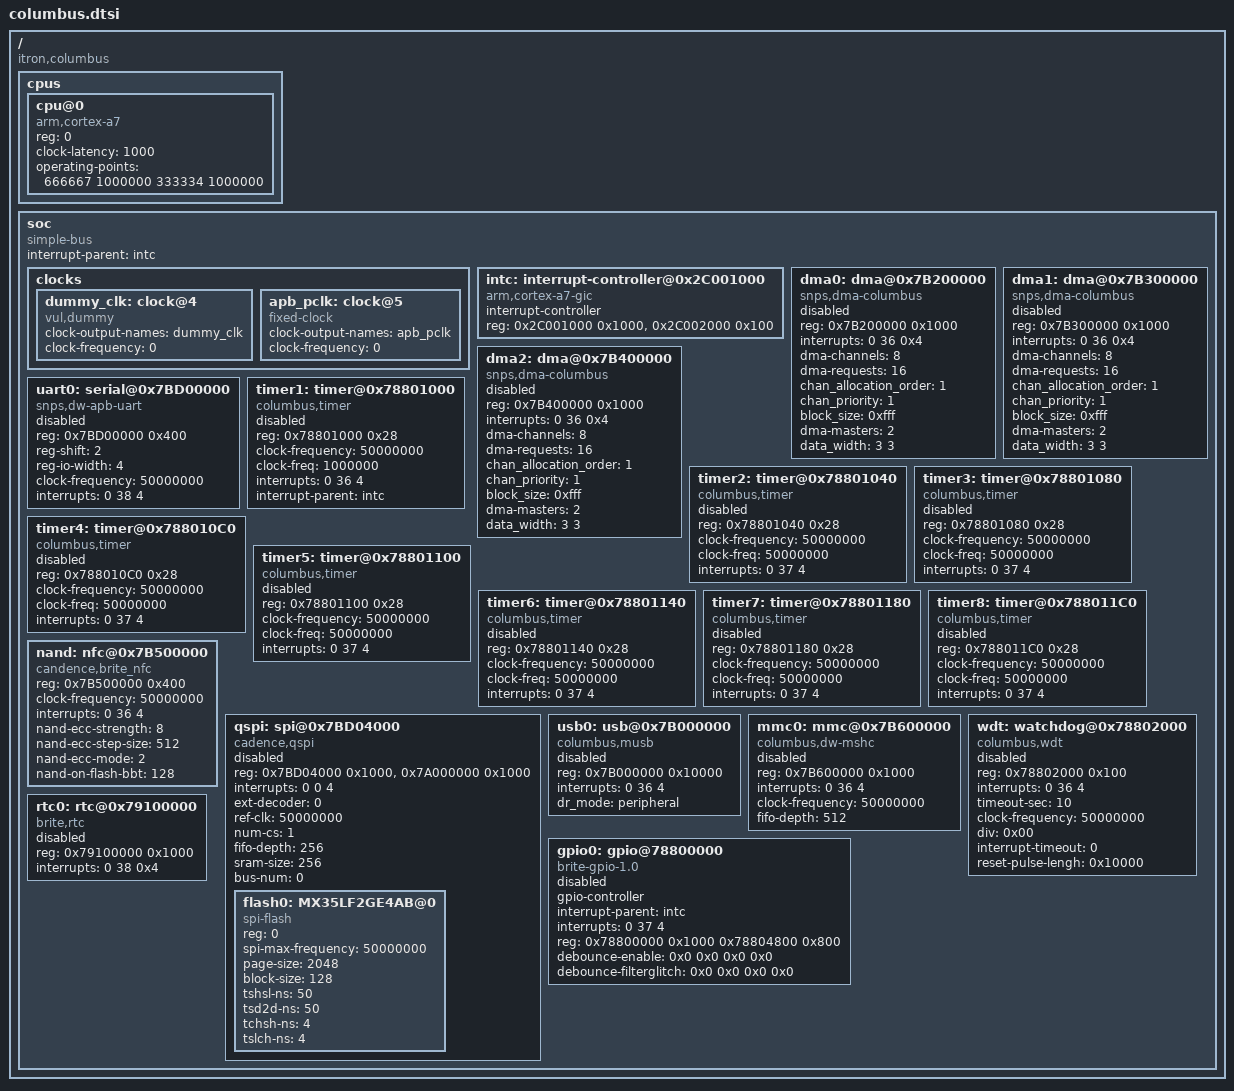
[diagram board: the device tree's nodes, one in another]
#include "skeleton.dtsi"

/ {
	compatible = "itron,columbus";

	cpus {
		#address-cells = <1>;
		#size-cells = <0>;

		cpu@0 {
			compatible = "arm,cortex-a7";
			device_type = "cpu";
			reg = <0>;
			clock-latency = <1000>;
			operating-points = <
				/* kHz    uV */
				666667  1000000
				333334  1000000
			>;
		};
	};

	soc {
		compatible = "simple-bus";
		#address-cells = <1>;
		#size-cells = <1>;
		interrupt-parent = <&intc>;
		ranges;

		clocks {
			dummy_clk: clock@4 {
				compatible = "vul,dummy", "fixed-clock";
				#clock-cells = <0>;
				clock-names = "dummy_clk";
				clock-output-names = "dummy_clk";
				clock-frequency = <0>;
			};
			apb_pclk: clock@5 {
				compatible = "fixed-clock";
				#clock-cells = <0>;
				clock-names = "apb_pclk";
				clock-output-names = "apb_pclk";
				clock-frequency = <0>;
			};
		};

		intc: interrupt-controller@0x2C001000 {
			compatible = "arm,cortex-a7-gic";
			#interrupt-cells = <3>;
			interrupt-controller;
			reg = <0x2C001000 0x1000>,
				<0x2C002000 0x100>;
		};

		dma0: dma@0x7B200000 {
                        compatible = "snps,dma-columbus";
                        reg = <0x7B200000 0x1000>;
                        interrupts = <0 36 0x4>;
                        status = "disabled";

                        dma-channels = <8>;
                        #dma-cells = <3>;
                        dma-requests = <16>;
                        chan_allocation_order = <1>;
                        chan_priority = <1>;
                        block_size = <0xfff>;
                        dma-masters = <2>;
                        data_width = <3 3>;
                };

                dma1: dma@0x7B300000 {
                        compatible = "snps,dma-columbus";
                        reg = <0x7B300000 0x1000>;
                        interrupts = <0 36 0x4>;
                        status = "disabled";

                        dma-channels = <8>;
                        #dma-cells = <3>;
                        dma-requests = <16>;
                        chan_allocation_order = <1>;
                        chan_priority = <1>;
                        block_size = <0xfff>;
                        dma-masters = <2>;
                        data_width = <3 3>;
                };

                dma2: dma@0x7B400000 {
                        compatible = "snps,dma-columbus";
                        reg = <0x7B400000 0x1000>;
                        interrupts = <0 36 0x4>;
                        status = "disabled";

                        dma-channels = <8>;
                        #dma-cells = <3>;
                        dma-requests = <16>;
                        chan_allocation_order = <1>;
                        chan_priority = <1>;
                        block_size = <0xfff>;
                        dma-masters = <2>;
                        data_width = <3 3>;
                };

  		uart0: serial@0x7BD00000 {
			compatible = "snps,dw-apb-uart";
			reg = <0x7BD00000 0x400>;
			reg-shift = <2>;
			reg-io-width = <4>;
			clock-frequency = <50000000>;
			interrupts = <0 38 4>;
			status = "disabled";
		};

		timer1: timer@0x78801000 {
			compatible = "columbus,timer";
			reg = <0x78801000 0x28>;
			clock-frequency = <50000000>;
			clock-freq = <1000000>;
			status = "disabled";
			interrupts = <0 36 4>;
			interrupt-parent = <&intc>;
		};
		timer2: timer@0x78801040 {
			compatible = "columbus,timer";
			reg = <0x78801040 0x28>;
			clock-frequency = <50000000>;
			clock-freq = <50000000>;
			interrupts = <0 37 4>;
			status = "disabled";
		};
		timer3: timer@0x78801080 {
			compatible = "columbus,timer";
			reg = <0x78801080 0x28>;
			clock-frequency = <50000000>;
			clock-freq = <50000000>;
			interrupts = <0 37 4>;
			status = "disabled";
		};
		timer4: timer@0x788010C0 {
			compatible = "columbus,timer";
			reg = <0x788010C0 0x28>;
			clock-frequency = <50000000>;
			clock-freq = <50000000>;
			interrupts = <0 37 4>;
			status = "disabled";
		};
		timer5: timer@0x78801100 {
			compatible = "columbus,timer";
			reg = <0x78801100 0x28>;
			clock-frequency = <50000000>;
			clock-freq = <50000000>;
			interrupts = <0 37 4>;
			status = "disabled";
		};
		timer6: timer@0x78801140 {
			compatible = "columbus,timer";
			reg = <0x78801140 0x28>;
			clock-frequency = <50000000>;
			clock-freq = <50000000>;
			interrupts = <0 37 4>;
			status = "disabled";
		};
		timer7: timer@0x78801180 {
			compatible = "columbus,timer";
			reg = <0x78801180 0x28>;
			clock-frequency = <50000000>;
			clock-freq = <50000000>;
			interrupts = <0 37 4>;
			status = "disabled";
		};
		timer8: timer@0x788011C0 {
			compatible = "columbus,timer";
			reg = <0x788011C0 0x28>;
			clock-frequency = <50000000>;
			clock-freq = <50000000>;
			interrupts = <0 37 4>;
			status = "disabled";
		};

		nand: nfc@0x7B500000 {
			compatible = "candence,brite_nfc";
			reg = <0x7B500000 0x400>;
			clock-frequency = <50000000>;
			interrupts = <0 36 4>;
			nand-ecc-strength = <8>;
			nand-ecc-step-size = <512>;
			nand-ecc-mode  = <2>;
			nand-on-flash-bbt = <128>;
		};
		qspi: spi@0x7BD04000 {
                        compatible = "cadence,qspi";
                        #address-cells = <1>;
                        #size-cells = <0>;
                        reg = <0x7BD04000 0x1000>,
                                <0x7A000000 0x1000>;
                        interrupts = <0 0 4>;
                        /*clocks = <&qspi_clk>;*/
                        ext-decoder = <0>;  /* external decoder */
                        ref-clk = <50000000>;
                        num-cs = <1>;
                        fifo-depth = <256>;
                        sram-size = <256>;
                        bus-num = <0>;
                        status = "disabled";

                        flash0: MX35LF2GE4AB@0 {
                                #address-cells = <1>;
                                #size-cells = <1>;
                                compatible = "spi-flash";
                                reg = <0>;              /* chip select */
                                spi-max-frequency = <50000000>;
                                page-size = <2048>;
                                block-size = <128>;      /* 128k */
                                tshsl-ns = <50>;
                                tsd2d-ns = <50>;
                                tchsh-ns = <4>;
                                tslch-ns = <4>;
                        };
                };

                usb0: usb@0x7B000000 {
                        compatible = "columbus,musb";
                        reg = <0x7B000000 0x10000>;
                        interrupts = <0 36 4>;
                        interrupt-names = "mc";
                        dr_mode = "peripheral";
                        status = "disabled";
                };
                mmc0: mmc@0x7B600000 {
                        compatible = "columbus,dw-mshc";
                        reg = <0x7B600000 0x1000>;
                        interrupts = <0 36 4>;
                        clock-frequency=<50000000>;
                        fifo-depth=<512>;
		      status = "disabled";
                };

                wdt: watchdog@0x78802000 {
                        compatible = "columbus,wdt";
		      reg = <0x78802000 0x100>;
		      interrupts = <0 36 4>;
                        timeout-sec = <10>;
                       /* reset-on-timeout = "true";*/
                        clock-frequency=<50000000>;
                        div=<0x00>;  /*default 1/2*/
                        interrupt-timeout=<0>; /*64k clk counter*/
                        reset-pulse-lengh=<0x10000>;
                        status = "disabled";
                };

                gpio0: gpio@78800000 {
                       #gpio-cells = <2>;
                       compatible = "brite-gpio-1.0";
                       //clocks = <&clkc 42>;
                       gpio-controller;
                       interrupt-parent = <&intc>;
                       interrupts = <0 37 4>;
                       reg = <0x78800000 0x1000 0x78804800 0x800>;
                       debounce-enable = <0x0 0x0 0x0 0x0>;
                       debounce-filterglitch = <0x0 0x0 0x0 0x0>;
                       status = "disabled";
               };

               rtc0: rtc@0x79100000 {
                                compatible = "brite,rtc";
                                reg = <0x79100000 0x1000>;
                                interrupts = <0 38 0x4>;
                                status = "disabled";
               };
	};
};

